VERSION ""

NS_ :

BS_:

BU_:
VAL_TABLE_ ODM_DBG_DCUStorageStatus 4 "DSS_FAILED_ODM_DBG" 3 "DSS_READY_NO_VALID_REC_ODM_DBG" 2 "DSS_READY_EMTY_ODM_DBG" 1 "DSS_READY_ODM_DBG" 0 "DSS_INITIALIZING_ODM_DBG" ;

BO_ 3221225472 VECTOR__INDEPENDENT_SIG_MSG: 0 Vector__XXX
 SG_ DBG_Calc_Error : 0|1@1+ (1,0) [0|1] "" Vector__XXX
 SG_ DBG_Flash_Error : 0|1@1+ (1,0) [0|1] "" Vector__XXX
 SG_ DBG_FlashTotVehDist_valid : 0|1@1+ (1,0) [0|1] "" Vector__XXX
 SG_ DBG_FlashTotVehDist_s : 0|2@1+ (1,0) [0|3] "" Vector__XXX
 SG_ DBG_FlashTotalECURunTime_s : 0|2@1+ (1,0) [0|3] "" Vector__XXX
 SG_ DBG_FlashTotalECURunTime : 0|16@1+ (1,0) [0|65535] "" Vector__XXX
 SG_ DBG_FlashLastUpTime : 0|16@1+ (1,0) [0|65535] "" Vector__XXX
 SG_ DBG_SrvMntnMilg : 0|16@1+ (1,0) [0|65535] "km" Vector__XXX
 SG_ DBG_LastUpTime : 0|32@1+ (1,0) [0|4294967295] "" Vector__XXX
 SG_ DBG_FlashStartTotVehDist_s : 0|2@1+ (1,0) [0|3] "" Vector__XXX
 SG_ DBG_HiResTotalVehDist_valid : 0|1@1+ (1,0) [0|1] "" Vector__XXX
 SG_ ODM_DBG_ODM_IsValid : 0|1@1+ (1,0) [0|0] "" Vector__XXX
 SG_ DBG_DCUStorageStatus : 0|8@1+ (1,0) [0|255] "" Vector__XXX
 SG_ ODO_DBG_TripDistance_m : 0|32@1+ (1,0) [0|4294967295] "m" Vector__XXX
 SG_ ODO_DBG_TotDistance_m : 0|32@1+ (1,0) [0|4294967295] "m" Vector__XXX

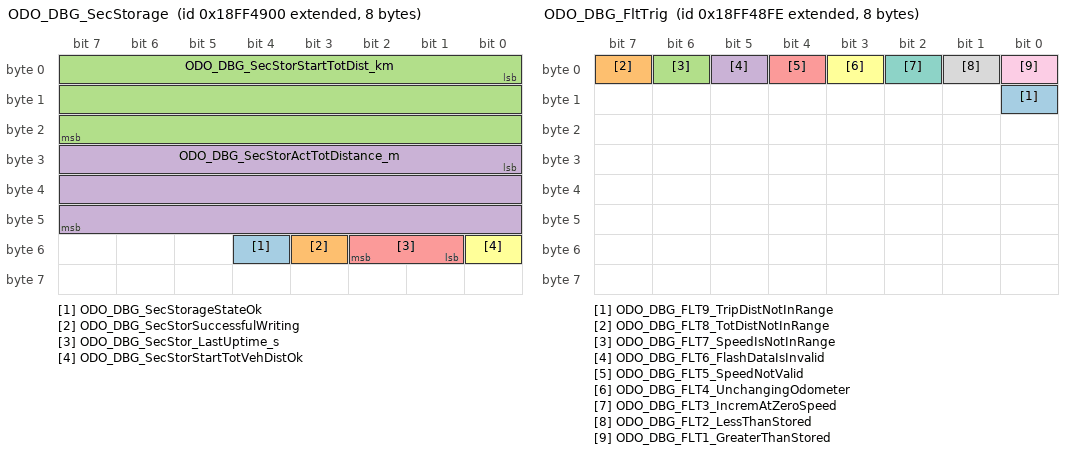
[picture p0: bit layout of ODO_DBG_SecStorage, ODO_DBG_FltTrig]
BO_ 2566867200 ODO_DBG_SecStorage: 8 Vector__XXX
 SG_ ODO_DBG_SecStorageStateOk : 52|1@1+ (1,0) [0|1] "" Vector__XXX
 SG_ ODO_DBG_SecStorSuccessfulWriting : 51|1@1+ (1,0) [0|1] "" Vector__XXX
 SG_ ODO_DBG_SecStorStartTotDist_km : 0|24@1+ (0.1,0) [0|1677721.5] "km" Vector__XXX
 SG_ ODO_DBG_SecStorActTotDistance_m : 24|24@1+ (1,0) [0|16777215] "m" Vector__XXX
 SG_ ODO_DBG_SecStor_LastUptime_s : 49|2@1+ (1,0) [0|3] "" Vector__XXX
 SG_ ODO_DBG_SecStorStartTotVehDistOk : 48|1@1+ (1,0) [0|1] "" Vector__XXX

BO_ 2566867198 ODO_DBG_FltTrig: 8 Vector__XXX
 SG_ ODO_DBG_FLT9_TripDistNotInRange : 8|1@1+ (1,0) [0|1] "" Vector__XXX
 SG_ ODO_DBG_FLT8_TotDistNotInRange : 7|1@1+ (1,0) [0|1] "" Vector__XXX
 SG_ ODO_DBG_FLT7_SpeedIsNotInRange : 6|1@1+ (1,0) [0|1] "" Vector__XXX
 SG_ ODO_DBG_FLT6_FlashDataIsInvalid : 5|1@1+ (1,0) [0|1] "" Vector__XXX
 SG_ ODO_DBG_FLT5_SpeedNotValid : 4|1@1+ (1,0) [0|1] "" Vector__XXX
 SG_ ODO_DBG_FLT4_UnchangingOdometer : 3|1@1+ (1,0) [0|1] "" Vector__XXX
 SG_ ODO_DBG_FLT3_IncremAtZeroSpeed : 2|1@1+ (1,0) [0|1] "" Vector__XXX
 SG_ ODO_DBG_FLT2_LessThanStored : 1|1@1+ (1,0) [0|1] "" Vector__XXX
 SG_ ODO_DBG_FLT1_GreaterThanStored : 0|1@1+ (1,0) [0|1] "" Vector__XXX

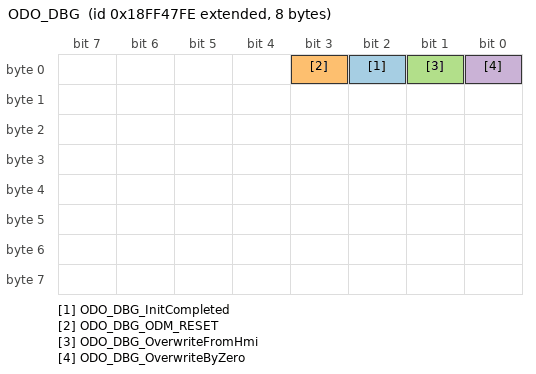
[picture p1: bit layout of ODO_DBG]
BO_ 2566866942 ODO_DBG: 8 Vector__XXX
 SG_ ODO_DBG_InitCompleted : 2|1@1+ (1,0) [0|1] "" Vector__XXX
 SG_ ODO_DBG_ODM_RESET : 3|1@1+ (1,0) [0|1] "" Vector__XXX
 SG_ ODO_DBG_OverwriteFromHmi : 1|1@1+ (1,0) [0|1] "" Vector__XXX
 SG_ ODO_DBG_OverwriteByZero : 0|1@1+ (1,0) [0|1] "" Vector__XXX

CM_ BO_ 3221225472 "This is a message for not used signals, created by Vector CANdb++ DBC OLE DB Provider.";
CM_ SG_ 3221225472 DBG_FlashStartTotVehDist_s "<HghRsolutionTotalVehDistanc_s>";
CM_ SG_ 3221225472 ODO_DBG_TripDistance_m "TripDistance_m";
CM_ SG_ 3221225472 ODO_DBG_TotDistance_m "TotDistance_m";
CM_ SG_ 2566867200 ODO_DBG_SecStorSuccessfulWriting "FramSuccessfulWriting";
CM_ SG_ 2566867200 ODO_DBG_SecStorStartTotDist_km "StartTotalDistance";
CM_ SG_ 2566867200 ODO_DBG_SecStorActTotDistance_m "ACTUAL Tota lDistance From Security Storage";
CM_ SG_ 2566867200 ODO_DBG_SecStor_LastUptime_s "SecStorage_LastUptime_s";
CM_ SG_ 2566867200 ODO_DBG_SecStorStartTotVehDistOk "start_SecStorage_TotVehDistOk";
CM_ SG_ 2566867198 ODO_DBG_FLT9_TripDistNotInRange "TripDistanceNotInRange";
CM_ SG_ 2566867198 ODO_DBG_FLT8_TotDistNotInRange "TotalDistanceNotInRange";
CM_ SG_ 2566867198 ODO_DBG_FLT7_SpeedIsNotInRange "SpeedIsNotInRange";
CM_ SG_ 2566867198 ODO_DBG_FLT6_FlashDataIsInvalid "FlashDataIsInvalid";
CM_ SG_ 2566867198 ODO_DBG_FLT5_SpeedNotValid "SpeedNotValid";
CM_ SG_ 2566867198 ODO_DBG_FLT4_UnchangingOdometer "UnchangingOdometer";
CM_ SG_ 2566867198 ODO_DBG_FLT3_IncremAtZeroSpeed "IncrementsAtZeroSpeed";
CM_ SG_ 2566866942 ODO_DBG_InitCompleted "DBG_InitCompleted";
CM_ SG_ 2566866942 ODO_DBG_ODM_RESET "DBG_ODM_Reset";
CM_ SG_ 2566866942 ODO_DBG_OverwriteFromHmi "DBG_OverwriteFromHmi";
CM_ SG_ 2566866942 ODO_DBG_OverwriteByZero "OverwriteByZero";
BA_DEF_ BO_  "SendOnChange" ENUM  "No","Yes";
BA_DEF_ BO_  "Producer" STRING ;
BA_DEF_ SG_  "SigType" ENUM  "Default","Range","RangeSigned","ASCII","Discrete","Control","ReferencePGN","DTC","StringDelimiter","StringLength","StringLengthControl","MessageCounter","MessageChecksum";
BA_DEF_ SG_  "GenSigEVName" STRING ;
BA_DEF_ SG_  "GenSigILSupport" ENUM  "No","Yes";
BA_DEF_ SG_  "GenSigSendType" ENUM  "Cyclic","OnWrite","OnWriteWithRepetition","OnChange","OnChangeWithRepetition","IfActive","IfActiveWithRepetition","NoSigSendType";
BA_DEF_ BO_  "GenMsgDelayTime" INT 0 1000;
BA_DEF_ BO_  "GenMsgILSupport" ENUM  "No","Yes";
BA_DEF_ BU_  "NmStationAddress" INT 0 255;
BA_DEF_ BO_  "GenMsgSendType" ENUM  "cyclic","NotUsed","IfActive","NotUsed","NotUsed","NotUsed","NotUsed","NotUsed","noMsgSendType";
BA_DEF_ BO_  "GenMsgRequestable" INT 0 1;
BA_DEF_ BO_  "GenMsgCycleTime" INT 0 3600000;
BA_DEF_  "DBName" STRING ;
BA_DEF_  "BusType" STRING ;
BA_DEF_  "ProtocolType" STRING ;
BA_DEF_ BO_  "VFrameFormat" ENUM  "StandardCAN","ExtendedCAN","reserved","J1939PG";
BA_DEF_DEF_  "SendOnChange" "No";
BA_DEF_DEF_ "Producer" "DTS" ;
BA_DEF_DEF_  "SigType" "Default";
BA_DEF_DEF_  "GenSigEVName" "Env@Nodename_@Signame";
BA_DEF_DEF_  "GenSigILSupport" "Yes";
BA_DEF_DEF_  "GenSigSendType" "NoSigSendType";
BA_DEF_DEF_  "GenMsgDelayTime" 0;
BA_DEF_DEF_  "GenMsgILSupport" "Yes";
BA_DEF_DEF_  "NmStationAddress" 254;
BA_DEF_DEF_  "GenMsgSendType" "noMsgSendType";
BA_DEF_DEF_  "GenMsgRequestable" 1;
BA_DEF_DEF_  "GenMsgCycleTime" 0;
BA_DEF_DEF_  "DBName" "";
BA_DEF_DEF_  "BusType" "CAN";
BA_DEF_DEF_  "ProtocolType" "J1939";
BA_DEF_DEF_  "VFrameFormat" "J1939PG";
BA_ "DBName" "J1939Template";
BA_ "GenMsgSendType" BO_ 2566867200 0;
BA_ "GenMsgCycleTime" BO_ 2566867200 100;
BA_ "GenMsgSendType" BO_ 2566867198 0;
BA_ "GenMsgCycleTime" BO_ 2566867198 100;
BA_ "SendOnChange" BO_ 2566867198 1;
BA_ "GenMsgDelayTime" BO_ 2566866942 100;
BA_ "GenMsgCycleTime" BO_ 2566866942 1000;
BA_ "GenMsgSendType" BO_ 2566866942 0;
BA_ "SendOnChange" BO_ 2566866942 1;
VAL_ 3221225472 DBG_FlashTotVehDist_s 2 "ODM_FLASH_ERR" 1 "ODM_FLASH_OK" 0 "ODM_FLASH_NA" ;
VAL_ 3221225472 DBG_FlashTotalECURunTime_s 2 "ODM_FLASH_ERR" 1 "ODM_FLASH_OK" 0 "ODM_FLASH_NA" ;
VAL_ 3221225472 DBG_FlashStartTotVehDist_s 2 "ODM_FLASH_ERR" 1 "ODM_FLASH_OK" 0 "ODM_FLASH_NA" ;
VAL_ 3221225472 DBG_DCUStorageStatus 4 "DSS_FAILED_ODM_DBG" 3 "DSS_READY_NO_VALID_REC_ODM_DBG" 2 "DSS_READY_EMTY_ODM_DBG" 1 "DSS_READY_ODM_DBG" 0 "DSS_INITIALIZING_ODM_DBG" ;
VAL_ 2566867200 ODO_DBG_SecStor_LastUptime_s 2 "ODM_FLASH_ERR" 1 "ODM_FLASH_OK" 0 "ODM_FLASH_NA" ;
